AUTOSAR XML (schema 4-2-2)
package /CDD_CORE3
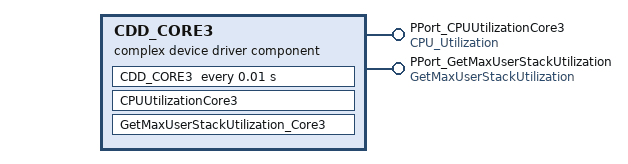
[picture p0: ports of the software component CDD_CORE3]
  complex device driver sw component type CDD_CORE3
    provide port PPort_CPUUtilizationCore3: provided-interface=CPU_Utilization
    provide port PPort_GetMaxUserStackUtilization: provided-interface=GetMaxUserStackUtilization
    behavior SwcInternalBehavior
      operation invoked event OperationInvokedEvent_0: start-on-event=CPUUtilizationCore3, operation=PPort_CPUUtilizationCore3.CPU_Utilization
      timing event TimingEvent_0: start-on-event=CDD_CORE3, period=0.01
      operation invoked event OperationInvokedEvent_1: start-on-event=GetMaxUserStackUtilization_Core3, operation=PPort_GetMaxUserStackUtilization.GetMaxUserStackUtilization
      runnable CPUUtilizationCore3: symbol=CPUUtilizationCore3_func
      runnable CDD_CORE3: symbol=CDD_CORE3_func
      runnable GetMaxUserStackUtilization_Core3: symbol=GetMaxUserStackUtilization_Core3_func
